# TLE984x register map
Vendor: Infineon Technologies AG; File version: 1.6
CPU: CM0 r0p0, little endian, no MPU, no FPU, 2 interrupt priority bits
Registers are 32-bit, read-write, no defined reset value unless marked. A register's access mark holds for its fields unless they carry their own. Offsets are from the block's base; [hi:lo] are bit positions; 'fields as' and 'values as' point back to an identical list.

## LS
Base 0x4001C000
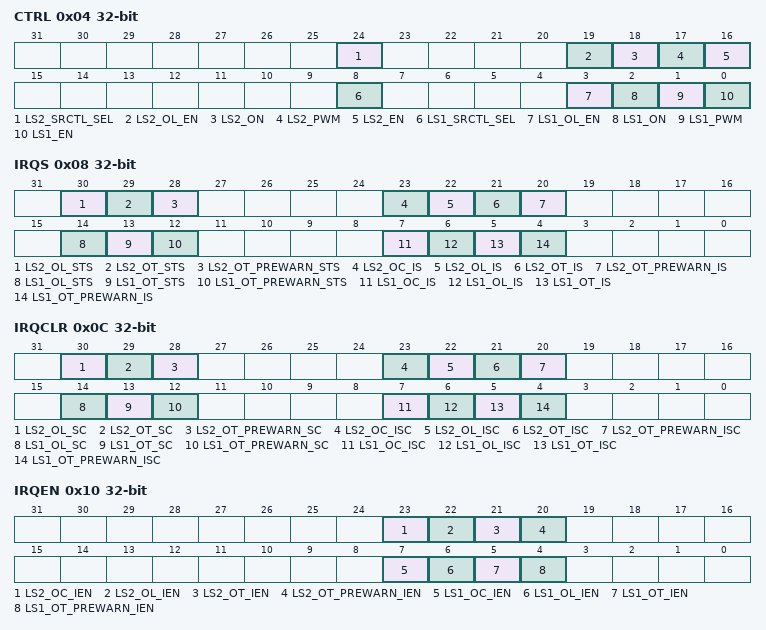
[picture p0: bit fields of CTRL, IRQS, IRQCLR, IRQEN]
0x04 CTRL — Low Side Driver Control
  [24] LS2_SRCTL_SEL — Low-Side switch 2 Slew Rate selection
    0=slow slew rate is selected; 1=fast slew rate is selected
  [19] LS2_OL_EN — Open load Detection Enable
    0=DISABLE (Open load detection); 1=ENABLE (Open load detection)
  [18] LS2_ON — Low-Side switch 2 On/Off
    0=OFF (switches LS2 off); 1=ON (turns on LS2)
  [17] LS2_PWM — Low-Side switch 2 PWM Enable
    0=DISABLE (normal mode controlled by LS2_ON); 1=ENABLE (enables LS2 for PWM mode)
  [16] LS2_EN — Low-Side switch 2 Enable
    0=DISABLE (disables LS2); 1=ENABLE (enables LS2)
  [8] LS1_SRCTL_SEL — Low-Side switch 1 Slew Rate selection
    0=slow slew rate is selected; 1=fast slew rate is selected
  [3] LS1_OL_EN — Open load Detection Enable
    values as LS2_OL_EN
  [2] LS1_ON — Low-Side switch 1 On/Off
    0=OFF (switches LS1 off); 1=ON (turns on LS1)
  [1] LS1_PWM — Low-Side switch 1 PWM Enable
    0=DISABLE (normal mode controlled by LS1_ON); 1=ENABLE (enables LS1 for PWM mode)
  [0] LS1_EN — Low-Side switch 1 Enable
    0=DISABLE (disables LS1); 1=ENABLE (enables LS1)
0x08 IRQS — Low Side Driver Interrupt Status
  [30] LS2_OL_STS — Low-Side 2 Open Load Status
    0=no open load Condition occurred; 1=open load occurred; switch is not automatically shutdown. Write sets status.
  [29] LS2_OT_STS — Low-Side 2 Overtemperature Status
    0=no overtemperature occurred; 1=overtemperature occurred; switch is automatically shutdown. Write sets status
  [28] LS2_OT_PREWARN_STS — Low-Side 2 Overtemperature Prewarning Status
    0=no overtemperature prewarn occurred; 1=overtemperature prewarn occurred; Write sets status
  [23] LS2_OC_IS — Low-Side 2 Overcurrent Interrupt Status
    0=no overcurrent Condition occurred; 1=overcurrent occurred; switch is automatically shutdown. Write sets status.
  [22] LS2_OL_IS — Low-Side 2 Open Load Interrupt Status
    values as LS2_OL_STS
  [21] LS2_OT_IS — Low-Side 2 Overtemperature Interrupt Status
    values as LS2_OT_STS
  [20] LS2_OT_PREWARN_IS — Low-Side 2 Overtemperature Prewarning Interrupt Status
    0=no overtemperature prewarn occurred; 1=overtemperature prewarn occurred. Write sets status
  [14] LS1_OL_STS — Low-Side 1 Open Load Status
    values as LS2_OL_STS
  [13] LS1_OT_STS — Low-Side 1 Overtemperature Status
    values as LS2_OT_STS
  [12] LS1_OT_PREWARN_STS — Low-Side 1 Overtemperature Prewarning Status
    values as LS2_OT_PREWARN_STS
  [7] LS1_OC_IS — Low-Side 1 Overcurrent Interrupt Status
    values as LS2_OC_IS
  [6] LS1_OL_IS — Low-Side 1 Open Load Interrupt Status
    values as LS2_OL_STS
  [5] LS1_OT_IS — Low-Side 1 Overtemperature Interrupt Status
    values as LS2_OT_STS
  [4] LS1_OT_PREWARN_IS — Low-Side 1 Overtemperature Prewarning Interrupt Status
    values as LS2_OT_PREWARN_IS
0x0C IRQCLR wo — Low Side Driver Interrupt Status Register Clear
  [30] LS2_OL_SC — Low-Side 2 Open Load status clear
    0=no Clear; 1=Clear
  [29] LS2_OT_SC — Low-Side switch 2 Overtemperature status Clear
    0=No Clear; 1=Clear
  [28] LS2_OT_PREWARN_SC — Low-Side 2 Overtemperature prewarn status clear
    0=No Clear; 1=Clear
  [23] LS2_OC_ISC — Low-Side 2 Overcurrent interrupt status clear
    0=No Clear; 1=Clear
  [22] LS2_OL_ISC — Low-Side 2 Open Load interrupt status clear
    0=no Clear; 1=Clear
  [21] LS2_OT_ISC — Low-Side 2 Overtemperature interrupt status clear
    0=No Clear; 1=Clear
  [20] LS2_OT_PREWARN_ISC — Low-Side 2Overtemperature prewarn interrupt status clear
    0=No Clear; 1=Clear
  [14] LS1_OL_SC — Low-Side 1 Open Load status clear
    0=no Clear; 1=Clear
  [13] LS1_OT_SC — Low-Side 1 Overtemperature status clear
    0=No Clear; 1=Clear
  [12] LS1_OT_PREWARN_SC — Low-Side 1 Overtemperature prewarn status clear
    0=No Clear; 1=Clear
  [7] LS1_OC_ISC — Low-Side 1 Overcurrent interrupt status clear
    0=No Clear; 1=Clear
  [6] LS1_OL_ISC — Low-Side 1 Open Load interrupt status clear
    0=no Clear; 1=Clear
  [5] LS1_OT_ISC — Low-Side 1 Overtemperature interrupt status clear
    0=No Clear; 1=Clear
  [4] LS1_OT_PREWARN_ISC — Low-Side 1 Overtemperature prewarn interrupt status clear
    0=No Clear; 1=Clear
0x10 IRQEN — Low Side Driver Interrupt Enable Register
  [23] LS2_OC_IEN — Low-Side 2 Overcurrent interrupt enable
    0=disable; 1=enable
  [22] LS2_OL_IEN — Low-Side 2 Open Load interrupt enable
    0=disable; 1=enable
  [21] LS2_OT_IEN — Low-Side 2 Overtemperature interrupt enable
    0=disabled; 1=enable
  [20] LS2_OT_PREWARN_IEN — Low-Side 2 Overtemperature prewarn interrupt enable
    0=disabled; 1=enable
  [7] LS1_OC_IEN — Low-Side 1 Overcurrent interrupt enable
    0=disable; 1=enable
  [6] LS1_OL_IEN — Low-Side 1 Open Load interrupt enable
    0=disable; 1=enable
  [5] LS1_OT_IEN — Low-Side 1 Overtemperature interrupt enable
    0=disabled; 1=enable
  [4] LS1_OT_PREWARN_IEN — Low-Side 1 Overtemperature prewarn interrupt enable
    0=disabled; 1=enable
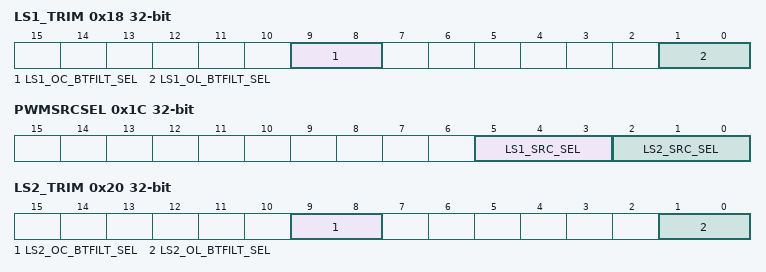
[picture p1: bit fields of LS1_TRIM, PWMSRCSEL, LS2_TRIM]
0x18 LS1_TRIM — Low Side Trimming Register
  [9:8] LS1_OC_BTFILT_SEL — Overcurrent BlankTime Select for LS1
    0=4 us filter time; 1=8 us filter time; 2=16 us filter time; 3=32 us filter time
  [1:0] LS1_OL_BTFILT_SEL — Open load Blank Time Select for LS1
    values as LS1_OC_BTFILT_SEL
0x1C PWMSRCSEL — Low Side PWM Source Selection Register
  [5:3] LS1_SRC_SEL — LS1 PWM Source Selection
    0=CC60 (PWM output of CCU6); 1=CC61 (PWM output of CCU6); 2=CC62 (PWM output of CCU6); 3=COUT60 (PWM output of CCU6); 4=COUT61 (PWM output of CCU6); 5=COUT62 (PWM output of CCU6); 6=T3OUT (PWM output of GPT12)
  [2:0] LS2_SRC_SEL — LS2 PWM Source Selection
    values as LS1_SRC_SEL
0x20 LS2_TRIM — Low Side Trimming Register
  [9:8] LS2_OC_BTFILT_SEL — Overcurrent BlankTime Select for LS2
    values as LS1_TRIM.LS1_OC_BTFILT_SEL
  [1:0] LS2_OL_BTFILT_SEL — Open load Blank Time Select for LS2
    values as LS1_TRIM.LS1_OC_BTFILT_SEL
